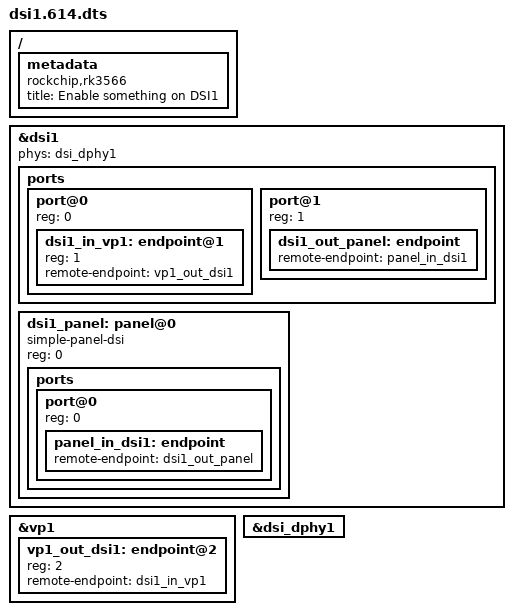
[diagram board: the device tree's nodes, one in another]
/dts-v1/;
/plugin/;

/ {
	metadata {
		title ="Enable something on DSI1";
		compatible = "rockchip,rk3566";
	};

	fragment@2 {
		target = <&dsi1>;

		__overlay__ {
			status = "okay";
			#address-cells = <1>;
			#size-cells = <0>;

			phys = <&dsi_dphy1>;

			ports {
				#address-cells = <1>;
				#size-cells = <0>;

				port@0 {
					#address-cells = <1>;
					#size-cells = <0>;

					reg = <0>;

					dsi1_in_vp1: endpoint@1 {
						reg = <1>;
						remote-endpoint = <&vp1_out_dsi1>;
						status = "okay";
						phandle = <0x8e>;
					};
				};

				port@1 {
					reg = <1>;
					dsi1_out_panel: endpoint {
						remote-endpoint = <&panel_in_dsi1>;
					};
				};
			};

			dsi1_panel: panel@0 {
				status = "okay";
				compatible = "simple-panel-dsi";
				reg = <0>;

				ports {
					#address-cells = <1>;
					#size-cells = <0>;

					port@0 {
						reg = <0>;

						panel_in_dsi1: endpoint {
							remote-endpoint = <&dsi1_out_panel>;
						};
					};
				};
			};
		};
	};

	fragment@4 {
		target = <&vp1>;

		__overlay__ {
			#address-cells = <1>;
			#size-cells = <0>;

			vp1_out_dsi1: endpoint@2 {
				reg = <2>;
				remote-endpoint = <&dsi1_in_vp1>;
			};
		};
	};

	fragment@5 {
		target = <&dsi_dphy1>;

		__overlay__ {
			status = "okay";
			// phy-supply = <&vdd_logic>;
		};
	};
};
